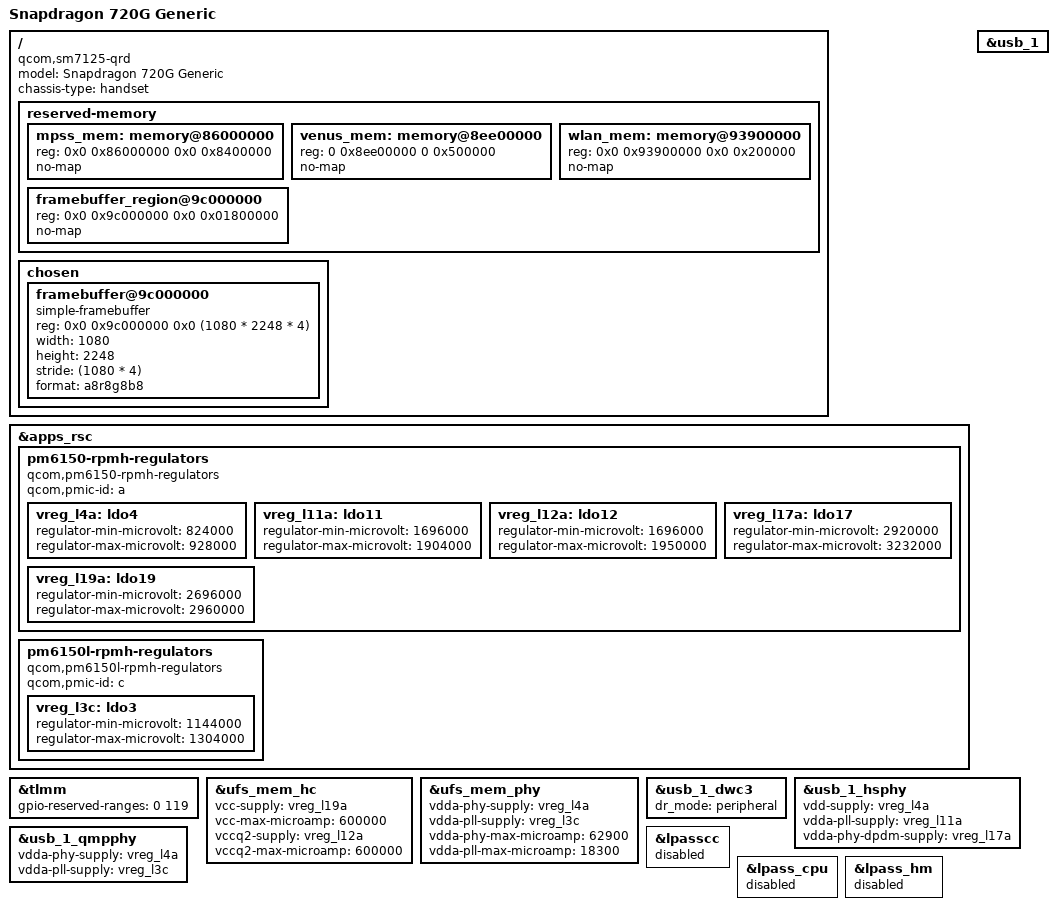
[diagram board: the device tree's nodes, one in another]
// SPDX-License-Identifier: BSD-3-Clause
/*
 * Copyright (c) 2022, Xilin Wu <strongtz@yeah.net>
 */

/dts-v1/;

#include <dt-bindings/gpio/gpio.h>
#include <dt-bindings/regulator/qcom,rpmh-regulator.h>

#include "sm7125.dtsi"
#include "pm6150.dtsi"
#include "pm6150l.dtsi"

/ {
	model = "Snapdragon 720G Generic";
	compatible = "qcom,sm7125-qrd", "qcom,sm7125", "qcom,sc7180";
	chassis-type = "handset";
	
	reserved-memory {
		#address-cells = <2>;
		#size-cells = <2>;
		ranges;

		mpss_mem: memory@86000000 {
			reg = <0x0 0x86000000 0x0 0x8400000>;
			no-map;
		};

		venus_mem: memory@8ee00000 {
			reg = <0 0x8ee00000 0 0x500000>;
			no-map;
		};

		wlan_mem: memory@93900000 {
			reg = <0x0 0x93900000 0x0 0x200000>;
			no-map;
		};

		framebuffer_region@9c000000 {
			reg = <0x0 0x9c000000 0x0 0x01800000>;
			no-map;
		};
	};

	chosen {
		#address-cells = <2>;
		#size-cells = <2>;
		ranges;
		framebuffer@9c000000 {
			compatible = "simple-framebuffer";
			reg = <0x0 0x9c000000 0x0 (1080 * 2248 * 4)>;
			width = <1080>;
			height = <2248>;
			stride = <(1080 * 4)>;
			format = "a8r8g8b8";
		};
	};
};

&apps_rsc {
	pm6150-rpmh-regulators {
		compatible = "qcom,pm6150-rpmh-regulators";
		qcom,pmic-id = "a";

		vreg_l4a: ldo4 {
			regulator-min-microvolt = <824000>;
			regulator-max-microvolt = <928000>;
		};

		vreg_l11a: ldo11 {
			regulator-min-microvolt = <1696000>;
			regulator-max-microvolt = <1904000>;
		};

		vreg_l12a: ldo12 {
			regulator-min-microvolt = <1696000>;
			regulator-max-microvolt = <1950000>;
		};

		vreg_l17a: ldo17 {
			regulator-min-microvolt = <2920000>;
			regulator-max-microvolt = <3232000>;
		};

		vreg_l19a: ldo19 {
			regulator-min-microvolt = <2696000>;
			regulator-max-microvolt = <2960000>;
		};
	};

	pm6150l-rpmh-regulators {
		compatible = "qcom,pm6150l-rpmh-regulators";
		qcom,pmic-id = "c";

		vreg_l3c: ldo3 {
			regulator-min-microvolt = <1144000>;
			regulator-max-microvolt = <1304000>;
		};
	};
};

&tlmm {
    // Reserve all
	gpio-reserved-ranges = <0 119>;
};

&ufs_mem_hc {
	status = "okay";

	vcc-supply = <&vreg_l19a>;
	vcc-max-microamp = <600000>;
	vccq2-supply = <&vreg_l12a>;
	vccq2-max-microamp = <600000>;
};

&ufs_mem_phy {
	status = "okay";

	vdda-phy-supply = <&vreg_l4a>;
	vdda-pll-supply = <&vreg_l3c>;
	vdda-phy-max-microamp = <62900>;
	vdda-pll-max-microamp = <18300>;
};

&usb_1 {
	status = "okay";
};

&usb_1_dwc3 {
	dr_mode = "peripheral";
};

&usb_1_hsphy {
	status = "okay";
	vdd-supply = <&vreg_l4a>;
	vdda-pll-supply = <&vreg_l11a>;
	vdda-phy-dpdm-supply = <&vreg_l17a>;
};

&usb_1_qmpphy {
	status = "okay";
	vdda-phy-supply = <&vreg_l4a>;
	vdda-pll-supply = <&vreg_l3c>;
};

&lpasscc {
	status = "disabled";
};

&lpass_cpu {
	status = "disabled";
};

&lpass_hm {
	status = "disabled";
};
